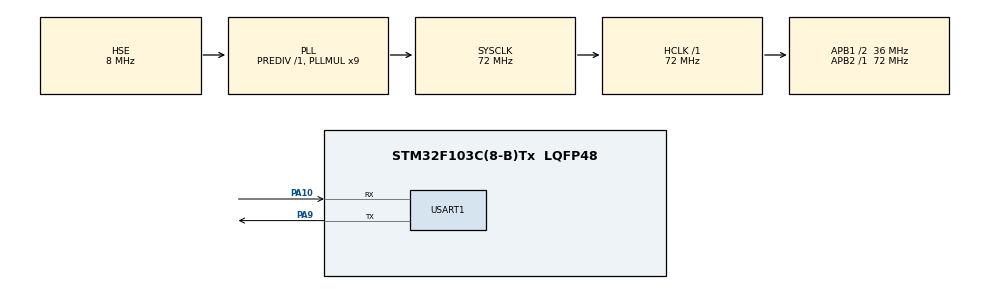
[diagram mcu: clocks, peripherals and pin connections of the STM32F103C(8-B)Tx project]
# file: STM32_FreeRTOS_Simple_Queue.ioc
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FREERTOS.Tasks01=defaultTask,0,128,StartDefaultTask,Default,NULL,Dynamic,NULL,NULL
FREERTOS.configUSE_NEWLIB_REENTRANT=1
Mcu.Family=STM32F1
Mcu.Name=STM32F103C(8-B)Tx
Mcu.Package=LQFP48
NVIC.PriorityGroup=NVIC_PRIORITYGROUP_4
NVIC.TIM2_IRQn=true\:15\:0\:false\:false\:true\:false\:false\:true\:true
NVIC.TimeBase=TIM2_IRQn
NVIC.TimeBaseIP=TIM2
NVIC.USART1_IRQn=true\:5\:0\:false\:false\:true\:true\:true\:true\:true
PA10.Mode=Asynchronous
PA10.Signal=USART1_RX
PA13.Mode=Serial_Wire
PA13.Signal=SYS_JTMS-SWDIO
PA14.Mode=Serial_Wire
PA14.Signal=SYS_JTCK-SWCLK
PA9.Mode=Asynchronous
PA9.Signal=USART1_TX
PD0-OSC_IN.Mode=HSE-External-Oscillator
PD0-OSC_IN.Signal=RCC_OSC_IN
PD1-OSC_OUT.Mode=HSE-External-Oscillator
PD1-OSC_OUT.Signal=RCC_OSC_OUT
ProjectManager.HeapSize=0x200
ProjectManager.StackSize=0x400
ProjectManager.TargetToolchain=STM32CubeIDE
RCC.AHBFreq_Value=72000000
RCC.APB1CLKDivider=RCC_HCLK_DIV2
RCC.APB1Freq_Value=36000000
RCC.APB1TimFreq_Value=72000000
RCC.APB2Freq_Value=72000000
RCC.APB2TimFreq_Value=72000000
RCC.HCLKFreq_Value=72000000
RCC.PLLMUL=RCC_PLL_MUL9
RCC.PLLSourceVirtual=RCC_PLLSOURCE_HSE
RCC.SYSCLKFreq_VALUE=72000000
RCC.SYSCLKSource=RCC_SYSCLKSOURCE_PLLCLK
RCC.USBFreq_Value=72000000
USART1.VirtualMode=VM_ASYNC
VP_FREERTOS_VS_CMSIS_V1.Mode=CMSIS_V1
VP_SYS_VS_tim2.Mode=TIM2
board=custom

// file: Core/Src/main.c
/* USER CODE BEGIN Header */
/**
 ******************************************************************************
 * @file           : main.c
 * @brief          : Main program body
 ******************************************************************************
 * @attention
 *
 * Copyright (c) 2026 STMicroelectronics.
 * All rights reserved.
 *
 * This software is licensed under terms that can be found in the LICENSE file
 * in the root directory of this software component.
 * If no LICENSE file comes with this software, it is provided AS-IS.
 *
 ******************************************************************************
 */
/* USER CODE END Header */
#include "main.h"

/* USER CODE BEGIN Includes */
#include "FreeRTOS.h"
#include "task.h"
#include "timers.h"
#include "queue.h"
#include "semphr.h"
#include "event_groups.h"

#include "string.h"
#include <stdio.h>
/* USER CODE END Includes */

UART_HandleTypeDef huart1;

void SystemClock_Config(void);
static void MX_GPIO_Init(void);
static void MX_USART1_UART_Init(void);

/* USER CODE BEGIN 0 */

// Tasks Handlers
xTaskHandle Sender_HPT_handler;
xTaskHandle Sender_LPT_handler;
xTaskHandle Receiver_handler;

// Queue Handler
xQueueHandle SimpleQueue;

uint8_t rx_data;

// Task Functions
void Sender_HPT_Task(void *argument);
void Sender_LPT_Task(void *argument);
void Receiver_Task(void *argument);

/* USER CODE END 0 */

int main(void)
{

  /* MCU Configuration--------------------------------------------------------*/

  /* Reset of all peripherals, Initializes the Flash interface and the Systick. */
  HAL_Init();

  /* Configure the system clock */
  SystemClock_Config();

  /* Initialize all configured peripherals */
  MX_GPIO_Init();
  MX_USART1_UART_Init();
  /* USER CODE BEGIN 2 */

  // Create queue
  SimpleQueue = xQueueCreate(5, sizeof(int));
  if(SimpleQueue == 0)
  {
    char *str = "Unable to create Simple queue\n\n\n";
    HAL_UART_Transmit(&huart1, (uint8_t*) str, strlen(str), HAL_MAX_DELAY);
  }
  else
  {
    char *str = "Simple queue Successfully Created\n\n\n";
    HAL_UART_Transmit(&huart1, (uint8_t*) str, strlen(str), HAL_MAX_DELAY);
  }

  // Create Tasks
  xTaskCreate(Sender_HPT_Task, "HPT_SEND", 128, NULL, 3, &Sender_HPT_handler);
  xTaskCreate(Sender_LPT_Task, "LPT_SEND", 128, (void*) 111, 2, &Sender_LPT_handler);

  xTaskCreate(Receiver_Task, "Receive", 128, NULL, 1, &Receiver_handler);

  HAL_UART_Receive_IT(&huart1, &rx_data, 1);

  vTaskStartScheduler();

  /* USER CODE END 2 */

  /* We should never get here as control is now taken by the scheduler */

  /* Infinite loop */
  while(1)
  {

  }
}

void SystemClock_Config(void)
{
  RCC_OscInitTypeDef RCC_OscInitStruct = {0};
  RCC_ClkInitTypeDef RCC_ClkInitStruct = {0};

  /** Initializes the RCC Oscillators according to the specified parameters
  * in the RCC_OscInitTypeDef structure.
  */
  RCC_OscInitStruct.OscillatorType = RCC_OSCILLATORTYPE_HSE;
  RCC_OscInitStruct.HSEState = RCC_HSE_ON;
  RCC_OscInitStruct.HSEPredivValue = RCC_HSE_PREDIV_DIV1;
  RCC_OscInitStruct.HSIState = RCC_HSI_ON;
  RCC_OscInitStruct.PLL.PLLState = RCC_PLL_ON;
  RCC_OscInitStruct.PLL.PLLSource = RCC_PLLSOURCE_HSE;
  RCC_OscInitStruct.PLL.PLLMUL = RCC_PLL_MUL9;
  if (HAL_RCC_OscConfig(&RCC_OscInitStruct) != HAL_OK)
  {
    Error_Handler();
  }

  /** Initializes the CPU, AHB and APB buses clocks
  */
  RCC_ClkInitStruct.ClockType = RCC_CLOCKTYPE_HCLK|RCC_CLOCKTYPE_SYSCLK
                              |RCC_CLOCKTYPE_PCLK1|RCC_CLOCKTYPE_PCLK2;
  RCC_ClkInitStruct.SYSCLKSource = RCC_SYSCLKSOURCE_PLLCLK;
  RCC_ClkInitStruct.AHBCLKDivider = RCC_SYSCLK_DIV1;
  RCC_ClkInitStruct.APB1CLKDivider = RCC_HCLK_DIV2;
  RCC_ClkInitStruct.APB2CLKDivider = RCC_HCLK_DIV1;

  if (HAL_RCC_ClockConfig(&RCC_ClkInitStruct, FLASH_LATENCY_2) != HAL_OK)
  {
    Error_Handler();
  }
}

static void MX_USART1_UART_Init(void)
{

  huart1.Instance = USART1;
  huart1.Init.BaudRate = 115200;
  huart1.Init.WordLength = UART_WORDLENGTH_8B;
  huart1.Init.StopBits = UART_STOPBITS_1;
  huart1.Init.Parity = UART_PARITY_NONE;
  huart1.Init.Mode = UART_MODE_TX_RX;
  huart1.Init.HwFlowCtl = UART_HWCONTROL_NONE;
  huart1.Init.OverSampling = UART_OVERSAMPLING_16;
  if (HAL_UART_Init(&huart1) != HAL_OK)
  {
    Error_Handler();
  }

}

static void MX_GPIO_Init(void)
{

  /* GPIO Ports Clock Enable */
  __HAL_RCC_GPIOD_CLK_ENABLE();
  __HAL_RCC_GPIOA_CLK_ENABLE();

}

/* USER CODE BEGIN 4 */

void Sender_HPT_Task(void *argument)
{
  int i = 222;
  uint32_t ticks = pdMS_TO_TICKS(2000);
  while(1)
  {
    char *str = "Entered Sender HPT Task\n about to send number to the queue\n\n";
    HAL_UART_Transmit(&huart1, (uint8_t*) str, strlen(str), HAL_MAX_DELAY);

    if(xQueueSend(SimpleQueue, &i, portMAX_DELAY) == pdPASS)
    {
      char *str2 = "Successfully sent the number to the queue\n Leaving Sender HPT Task\n\n";
      HAL_UART_Transmit(&huart1, (uint8_t*) str2, strlen(str2), HAL_MAX_DELAY);
    }

    vTaskDelay(ticks);
  }
}

void Sender_LPT_Task(void *argument)
{
  int to_send;
  uint32_t ticks = pdMS_TO_TICKS(1000);
  while(1)
  {
    to_send = (int) argument;
    char *str = "Entered Sender LPT Task\n about to send number to the queue\n\n";
    HAL_UART_Transmit(&huart1, (uint8_t*) str, strlen(str), HAL_MAX_DELAY);

    xQueueSend(SimpleQueue, &to_send, portMAX_DELAY);

    char *str2 = "Successfully sent the number to the queue\n Leaving Sender LPT Task\n\n";
    HAL_UART_Transmit(&huart1, (uint8_t*) str2, strlen(str2), HAL_MAX_DELAY);

    vTaskDelay(ticks);
  }
}

void Receiver_Task(void *argument)
{
  int received = 0;
  uint32_t ticks = pdMS_TO_TICKS(5000);
  while(1)
  {
    char str[100];
    strcpy(str, "Entered Receiver Task\n about to receive a number from the queue\n\n");
    HAL_UART_Transmit(&huart1, (uint8_t*) str, strlen(str), HAL_MAX_DELAY);

    if(xQueueReceive(SimpleQueue, &received, portMAX_DELAY) != pdTRUE)
    {
      HAL_UART_Transmit(&huart1, (uint8_t*) "Error in Receiving from the queue\n\n", 35, 1000);
    }
    else
    {
      sprintf(str, "Successfully received the number %d from the queue\n Leaving Receiver Task\n\n", received);
      HAL_UART_Transmit(&huart1, (uint8_t*) str, strlen(str), HAL_MAX_DELAY);
    }

    vTaskDelay(ticks);
  }
}

// ISR callback function
void HAL_UART_RxCpltCallback(UART_HandleTypeDef *huart)
{
  HAL_UART_Receive_IT(&huart1, &rx_data, 1);
  int to_send = 12345;
  if(rx_data == 'r')
  {
    BaseType_t pxHigherPriorityTaskWoken = pdFALSE;

    if (xQueueSendToBackFromISR(SimpleQueue, &to_send, &pxHigherPriorityTaskWoken))
    {
      HAL_UART_Transmit(&huart1, (uint8_t*) "Sent from ISR\n\n", 15, 500);
    }

    portEND_SWITCHING_ISR(pxHigherPriorityTaskWoken);
  }
}

/* USER CODE END 4 */

void HAL_TIM_PeriodElapsedCallback(TIM_HandleTypeDef *htim)
{
  if (htim->Instance == TIM2)
  {
    HAL_IncTick();
  }
}

void Error_Handler(void)
{
  __disable_irq();
  while(1)
  {
  }
}
